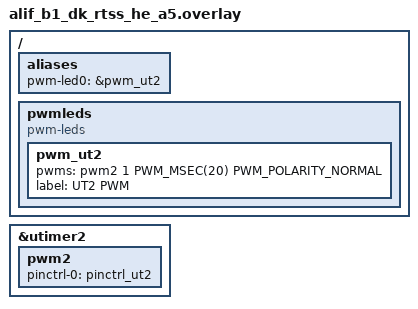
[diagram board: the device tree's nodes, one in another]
/* Copyright (c) 2025 Alif Semiconductor
 *
 * SPDX-License-Identifier: Apache-2.0
 */

/ {
	aliases {
		pwm-led0 = &pwm_ut2;
	};

	pwmleds {
		compatible = "pwm-leds";
		pwm_ut2: pwm_ut2 {
			pwms = <&pwm2 1 PWM_MSEC(20) PWM_POLARITY_NORMAL>;
			label = "UT2 PWM";
		};
	};
};

&utimer2 {
	status = "okay";

	pwm2: pwm2 {
		pinctrl-0 = < &pinctrl_ut2 >;
		pinctrl-names = "default";
		status = "okay";
	};
};
